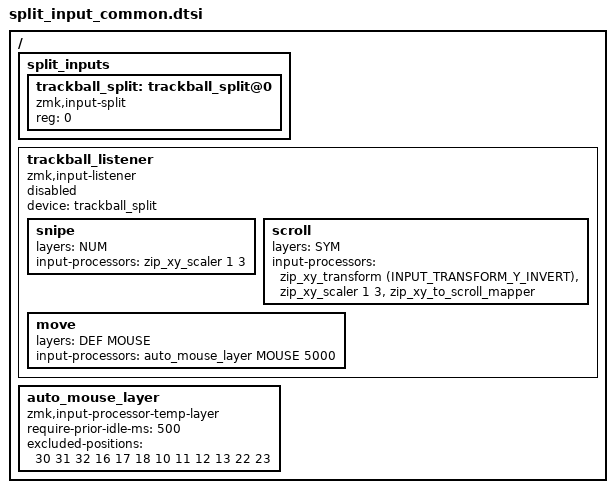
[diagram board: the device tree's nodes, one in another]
#include <dt-bindings/zmk/input_transform.h>
#include <input/processors.dtsi>

#define DEF 0
#define MOUSE 1
#define SYM 2
#define NUM 3
#define FN 4
#define GENSHIN 5 

/ {
  split_inputs {
    #address-cells = <1>;
    #size-cells = <0>;

    trackball_split: trackball_split@0 {
      compatible = "zmk,input-split";
      reg = <0>;
    };
  };

  trackball_listener: trackball_listener {
    compatible = "zmk,input-listener";
    status = "disabled";
    device = <&trackball_split>;

    snipe {
      layers = <NUM>;
      input-processors = <&zip_xy_scaler 1 3>;
    };

    scroll {
      layers = <SYM>;
      input-processors = <&zip_xy_transform (INPUT_TRANSFORM_Y_INVERT)>, <&zip_xy_scaler 1 3>, <&zip_xy_to_scroll_mapper>;
    };

    move {
      layers = <DEF MOUSE>;
      input-processors = <&auto_mouse_layer MOUSE 5000>;
    };
  };

  auto_mouse_layer: auto_mouse_layer {
    compatible = "zmk,input-processor-temp-layer";
    #input-processor-cells = <2>;
    require-prior-idle-ms = <500>;
    excluded-positions = <30 31 32 16 17 18 10 11 12 13 22 23>;
  };
};

